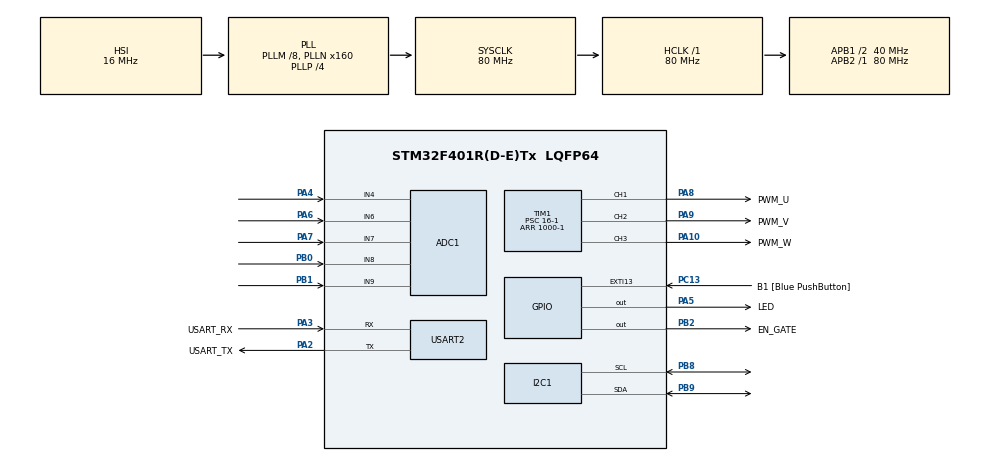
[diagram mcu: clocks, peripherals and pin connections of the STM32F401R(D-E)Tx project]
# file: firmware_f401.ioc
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ADC1.Channel-1\#ChannelRegularConversion=ADC_CHANNEL_4
ADC1.Channel-2\#ChannelRegularConversion=ADC_CHANNEL_6
ADC1.Channel-3\#ChannelRegularConversion=ADC_CHANNEL_7
ADC1.Channel-4\#ChannelRegularConversion=ADC_CHANNEL_8
ADC1.Channel-5\#ChannelRegularConversion=ADC_CHANNEL_9
ADC1.ContinuousConvMode=DISABLE
ADC1.DMAContinuousRequests=ENABLE
ADC1.DiscontinuousConvMode=DISABLE
ADC1.ExternalTrigConv=ADC_EXTERNALTRIGCONV_T3_TRGO
ADC1.NbrOfConversion=5
ADC1.NbrOfConversionFlag=1
ADC1.Rank-1\#ChannelRegularConversion=1
ADC1.Rank-2\#ChannelRegularConversion=2
ADC1.Rank-3\#ChannelRegularConversion=3
ADC1.Rank-4\#ChannelRegularConversion=4
ADC1.Rank-5\#ChannelRegularConversion=5
ADC1.SamplingTime-1\#ChannelRegularConversion=ADC_SAMPLETIME_56CYCLES
ADC1.SamplingTime-2\#ChannelRegularConversion=ADC_SAMPLETIME_56CYCLES
ADC1.SamplingTime-3\#ChannelRegularConversion=ADC_SAMPLETIME_56CYCLES
ADC1.SamplingTime-4\#ChannelRegularConversion=ADC_SAMPLETIME_56CYCLES
ADC1.SamplingTime-5\#ChannelRegularConversion=ADC_SAMPLETIME_56CYCLES
ADC1.ScanConvMode=ENABLE
ADC1.master=1
Dma.ADC1.0.Direction=DMA_PERIPH_TO_MEMORY
Dma.ADC1.0.FIFOMode=DMA_FIFOMODE_DISABLE
Dma.ADC1.0.Instance=DMA2_Stream0
Dma.ADC1.0.MemDataAlignment=DMA_MDATAALIGN_HALFWORD
Dma.ADC1.0.MemInc=DMA_MINC_ENABLE
Dma.ADC1.0.Mode=DMA_CIRCULAR
Dma.ADC1.0.PeriphDataAlignment=DMA_PDATAALIGN_HALFWORD
Dma.ADC1.0.PeriphInc=DMA_PINC_DISABLE
Dma.ADC1.0.Priority=DMA_PRIORITY_LOW
Dma.Request0=ADC1
Mcu.Family=STM32F4
Mcu.Name=STM32F401R(D-E)Tx
Mcu.Package=LQFP64
NVIC.DMA2_Stream0_IRQn=true\:0\:0\:false\:false\:true\:false\:true
NVIC.PriorityGroup=NVIC_PRIORITYGROUP_0
NVIC.TIM1_TRG_COM_TIM11_IRQn=true\:0\:0\:false\:false\:true\:true\:true
NVIC.TIM1_UP_TIM10_IRQn=true\:0\:0\:false\:false\:true\:true\:true
NVIC.TIM3_IRQn=true\:0\:0\:false\:false\:true\:true\:true
PA10.GPIO_Label=PWM_W
PA10.Signal=S_TIM1_CH3
PA13.GPIO_Label=TMS
PA13.Mode=Serial_Wire
PA13.Signal=SYS_JTMS-SWDIO
PA14.GPIO_Label=TCK
PA14.Mode=Serial_Wire
PA14.Signal=SYS_JTCK-SWCLK
PA2.GPIO_Label=USART_TX
PA2.GPIO_Mode=GPIO_MODE_AF_PP
PA2.GPIO_PuPd=GPIO_NOPULL
PA2.GPIO_Speed=GPIO_SPEED_FREQ_LOW
PA2.Mode=Asynchronous
PA2.Signal=USART2_TX
PA3.GPIO_Label=USART_RX
PA3.GPIO_Mode=GPIO_MODE_AF_PP
PA3.GPIO_PuPd=GPIO_NOPULL
PA3.GPIO_Speed=GPIO_SPEED_FREQ_LOW
PA3.Mode=Asynchronous
PA3.Signal=USART2_RX
PA4.Signal=ADCx_IN4
PA5.GPIO_Label=LED
PA5.GPIO_PuPd=GPIO_NOPULL
PA5.GPIO_Speed=GPIO_SPEED_FREQ_LOW
PA5.Signal=GPIO_Output
PA6.Signal=ADCx_IN6
PA7.Signal=ADCx_IN7
PA8.GPIO_Label=PWM_U
PA8.Signal=S_TIM1_CH1
PA9.GPIO_Label=PWM_V
PA9.Signal=S_TIM1_CH2
PB0.Signal=ADCx_IN8
PB1.Signal=ADCx_IN9
PB2.GPIO_Label=EN_GATE
PB2.Signal=GPIO_Output
PB3.GPIO_Label=SWO
PB3.Signal=SYS_JTDO-SWO
PB8.GPIO_Pu=GPIO_PULLUP
PB8.Mode=I2C
PB8.Signal=I2C1_SCL
PB9.GPIO_Pu=GPIO_PULLUP
PB9.Mode=I2C
PB9.Signal=I2C1_SDA
PC13-ANTI_TAMP.GPIO_Label=B1 [Blue PushButton]
PC13-ANTI_TAMP.GPIO_ModeDefaultEXTI=GPIO_MODE_IT_FALLING
PC13-ANTI_TAMP.GPIO_PuPd=GPIO_NOPULL
PC13-ANTI_TAMP.Signal=GPXTI13
PC14-OSC32_IN.Mode=LSE-External-Oscillator
PC14-OSC32_IN.Signal=RCC_OSC32_IN
PC15-OSC32_OUT.Mode=LSE-External-Oscillator
PC15-OSC32_OUT.Signal=RCC_OSC32_OUT
PH0\ -\ OSC_IN.Mode=HSE-External-Clock-Source
PH0\ -\ OSC_IN.Signal=RCC_OSC_IN
PH1\ -\ OSC_OUT.Mode=HSE-External-Clock-Source
PH1\ -\ OSC_OUT.Signal=RCC_OSC_OUT
ProjectManager.HeapSize=0x200
ProjectManager.StackSize=0x400
ProjectManager.TargetToolchain=Makefile
RCC.48MHZClocksFreq_Value=45714285.71428572
RCC.AHBFreq_Value=80000000
RCC.APB1CLKDivider=RCC_HCLK_DIV2
RCC.APB1Freq_Value=40000000
RCC.APB1TimFreq_Value=80000000
RCC.APB2Freq_Value=80000000
RCC.APB2TimFreq_Value=80000000
RCC.CortexFreq_Value=80000000
RCC.HCLKFreq_Value=80000000
RCC.HSE_VALUE=8000000
RCC.HSI_VALUE=16000000
RCC.PLLM=8
RCC.PLLN=160
RCC.PLLP=RCC_PLLP_DIV4
RCC.PLLQ=7
RCC.SYSCLKFreq_VALUE=80000000
RCC.SYSCLKSource=RCC_SYSCLKSOURCE_PLLCLK
RCC.VCOOutputFreq_Value=320000000
SH.ADCx_IN4.0=ADC1_IN4,IN4
SH.ADCx_IN6.0=ADC1_IN6,IN6
SH.ADCx_IN7.0=ADC1_IN7,IN7
SH.ADCx_IN8.0=ADC1_IN8,IN8
SH.ADCx_IN9.0=ADC1_IN9,IN9
SH.S_TIM1_CH1.0=TIM1_CH1,PWM Generation1 CH1
SH.S_TIM1_CH2.0=TIM1_CH2,PWM Generation2 CH2
SH.S_TIM1_CH3.0=TIM1_CH3,PWM Generation3 CH3
TIM1.AutoReloadPreload=TIM_AUTORELOAD_PRELOAD_DISABLE
TIM1.Channel-PWM\ Generation1\ CH1=TIM_CHANNEL_1
TIM1.Channel-PWM\ Generation2\ CH2=TIM_CHANNEL_2
TIM1.Channel-PWM\ Generation3\ CH3=TIM_CHANNEL_3
TIM1.OC1Preload_PWM=ENABLE
TIM1.OffStateIDLEMode=TIM_OSSI_ENABLE
TIM1.Period=1000-1
TIM1.Prescaler=16-1
TIM11.Period=10000-1
TIM11.Prescaler=16-1
TIM3.Period=1000-1
TIM3.Prescaler=16-1
TIM3.TIM_MasterOutputTrigger=TIM_TRGO_UPDATE
USART2.VirtualMode=VM_ASYNC
VP_TIM11_VS_ClockSourceINT.Mode=Enable_Timer
VP_TIM1_VS_ClockSourceINT.Mode=Internal
VP_TIM3_VS_ClockSourceINT.Mode=Internal
board=NUCLEO-F401RE

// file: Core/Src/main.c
/* USER CODE BEGIN Header */
/**
  ******************************************************************************
  * @file           : main.c
  * @brief          : Main program body
  ******************************************************************************
  * @attention
  *
  * Copyright (c) 2022 STMicroelectronics.
  * All rights reserved.
  *
  * This software is licensed under terms that can be found in the LICENSE file
  * in the root directory of this software component.
  * If no LICENSE file comes with this software, it is provided AS-IS.
  *
  ******************************************************************************
  */
/* USER CODE END Header */
#include "main.h"
#include "adc.h"
#include "dma.h"
#include "i2c.h"
#include "tim.h"
#include "usart.h"
#include "gpio.h"

/* USER CODE BEGIN Includes */
#include "user_include/user_main.h"
/* USER CODE END Includes */

void SystemClock_Config(void);

int main(void)
{

  /* MCU Configuration--------------------------------------------------------*/

  /* Reset of all peripherals, Initializes the Flash interface and the Systick. */
  HAL_Init();

  /* Configure the system clock */
  SystemClock_Config();

  /* Initialize all configured peripherals */
  MX_GPIO_Init();
  MX_DMA_Init();
  MX_ADC1_Init();
  MX_I2C1_Init();
  MX_TIM1_Init();
  MX_TIM11_Init();
  MX_USART2_UART_Init();
  MX_TIM3_Init();
  /* USER CODE BEGIN 2 */
  user_setup();
  /* USER CODE END 2 */

  /* Infinite loop */
  /* USER CODE BEGIN WHILE */
  while (1)
  {
	  user_loop();

    /* USER CODE END WHILE */

  }
}

void SystemClock_Config(void)
{
  RCC_OscInitTypeDef RCC_OscInitStruct = {0};
  RCC_ClkInitTypeDef RCC_ClkInitStruct = {0};

  /** Configure the main internal regulator output voltage
  */
  __HAL_RCC_PWR_CLK_ENABLE();
  __HAL_PWR_VOLTAGESCALING_CONFIG(PWR_REGULATOR_VOLTAGE_SCALE2);
  /** Initializes the RCC Oscillators according to the specified parameters
  * in the RCC_OscInitTypeDef structure.
  */
  RCC_OscInitStruct.OscillatorType = RCC_OSCILLATORTYPE_HSI;
  RCC_OscInitStruct.HSIState = RCC_HSI_ON;
  RCC_OscInitStruct.HSICalibrationValue = RCC_HSICALIBRATION_DEFAULT;
  RCC_OscInitStruct.PLL.PLLState = RCC_PLL_ON;
  RCC_OscInitStruct.PLL.PLLSource = RCC_PLLSOURCE_HSI;
  RCC_OscInitStruct.PLL.PLLM = 8;
  RCC_OscInitStruct.PLL.PLLN = 160;
  RCC_OscInitStruct.PLL.PLLP = RCC_PLLP_DIV4;
  RCC_OscInitStruct.PLL.PLLQ = 7;
  if (HAL_RCC_OscConfig(&RCC_OscInitStruct) != HAL_OK)
  {
    Error_Handler();
  }
  /** Initializes the CPU, AHB and APB buses clocks
  */
  RCC_ClkInitStruct.ClockType = RCC_CLOCKTYPE_HCLK|RCC_CLOCKTYPE_SYSCLK
                              |RCC_CLOCKTYPE_PCLK1|RCC_CLOCKTYPE_PCLK2;
  RCC_ClkInitStruct.SYSCLKSource = RCC_SYSCLKSOURCE_PLLCLK;
  RCC_ClkInitStruct.AHBCLKDivider = RCC_SYSCLK_DIV1;
  RCC_ClkInitStruct.APB1CLKDivider = RCC_HCLK_DIV2;
  RCC_ClkInitStruct.APB2CLKDivider = RCC_HCLK_DIV1;

  if (HAL_RCC_ClockConfig(&RCC_ClkInitStruct, FLASH_LATENCY_2) != HAL_OK)
  {
    Error_Handler();
  }
}

void Error_Handler(void)
{
  __disable_irq();
  while (1)
  {
  }
}
